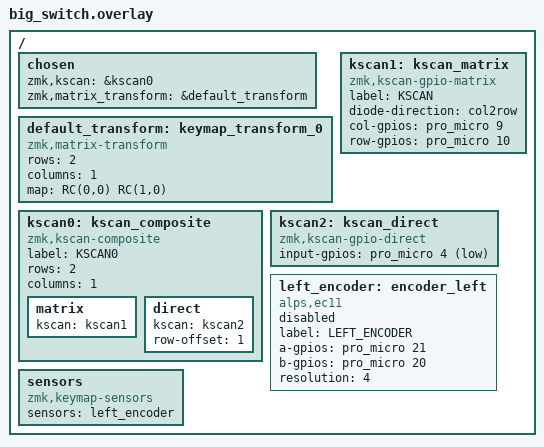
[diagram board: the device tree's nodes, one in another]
#include <dt-bindings/zmk/matrix_transform.h>

/ {
    chosen {
        zmk,kscan = &kscan0;
        zmk,matrix_transform = &default_transform;
    };

    default_transform: keymap_transform_0 {
        compatible = "zmk,matrix-transform";
        rows = <2>;
        columns = <1>;
        map = <RC(0,0) RC(1,0)>;
    };

    kscan0: kscan_composite {
        compatible = "zmk,kscan-composite";
        label = "KSCAN0";
        rows = <2>;
        columns = <1>;

        matrix {
            kscan = <&kscan1>;
        };

        direct {
            kscan = <&kscan2>;
            row-offset = <1>;
        };

    };

    kscan1: kscan_matrix {
        compatible = "zmk,kscan-gpio-matrix";
        label = "KSCAN";
        diode-direction = "col2row";

       col-gpios
            = <&pro_micro  9 GPIO_ACTIVE_HIGH>
            ;

       row-gpios
            = <&pro_micro 10 (GPIO_ACTIVE_HIGH | GPIO_PULL_DOWN)>
            ;
    };

    kscan2: kscan_direct {
        compatible = "zmk,kscan-gpio-direct";
        input-gpios
            = <&pro_micro 4 (GPIO_ACTIVE_LOW | GPIO_PULL_UP)>
            ;
    };

    left_encoder: encoder_left {
        compatible = "alps,ec11";
        label = "LEFT_ENCODER";
        a-gpios = <&pro_micro 21 (GPIO_ACTIVE_HIGH | GPIO_PULL_UP)>;
        b-gpios = <&pro_micro 20 (GPIO_ACTIVE_HIGH | GPIO_PULL_UP)>;
        resolution = <4>;
        status = "disabled";
    };

    sensors {
        compatible = "zmk,keymap-sensors";
        sensors = <&left_encoder>;
    };

};
// vim:ft=dts

